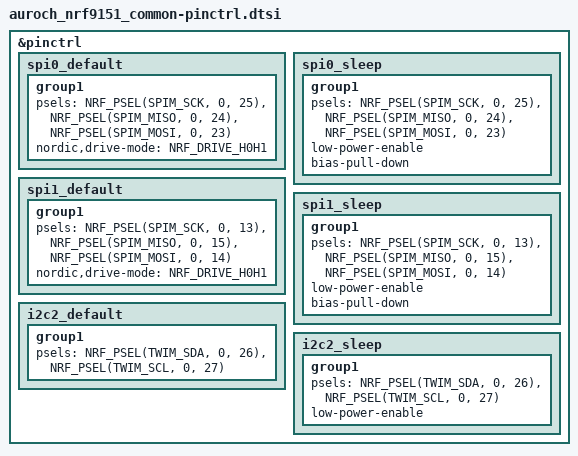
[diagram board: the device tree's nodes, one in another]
/*
 * Copyright (c) 2025 Embeint Holdings Pty Ltd
 * SPDX-License-Identifier: Apache-2.0
 */

&pinctrl {
	spi0_default: spi0_default {
		group1 {
			psels = <NRF_PSEL(SPIM_SCK, 0, 25)>,
				<NRF_PSEL(SPIM_MISO, 0, 24)>,
				<NRF_PSEL(SPIM_MOSI, 0, 23)>;
			nordic,drive-mode = <NRF_DRIVE_H0H1>;
		};
	};

	spi0_sleep: spi0_sleep {
		group1 {
			psels = <NRF_PSEL(SPIM_SCK, 0, 25)>,
				<NRF_PSEL(SPIM_MISO, 0, 24)>,
				<NRF_PSEL(SPIM_MOSI, 0, 23)>;
			low-power-enable;
			bias-pull-down;
		};
	};

	spi1_default: spi1_default {
		group1 {
			psels = <NRF_PSEL(SPIM_SCK, 0, 13)>,
				<NRF_PSEL(SPIM_MISO, 0, 15)>,
				<NRF_PSEL(SPIM_MOSI, 0, 14)>;
			nordic,drive-mode = <NRF_DRIVE_H0H1>;
		};
	};

	spi1_sleep: spi1_sleep {
		group1 {
			psels = <NRF_PSEL(SPIM_SCK, 0, 13)>,
				<NRF_PSEL(SPIM_MISO, 0, 15)>,
				<NRF_PSEL(SPIM_MOSI, 0, 14)>;
			low-power-enable;
			bias-pull-down;
		};
	};

	i2c2_default: i2c2_default {
		group1 {
			psels = <NRF_PSEL(TWIM_SDA, 0, 26)>,
				<NRF_PSEL(TWIM_SCL, 0, 27)>;
		};
	};

	i2c2_sleep: i2c2_sleep {
		group1 {
			psels = <NRF_PSEL(TWIM_SDA, 0, 26)>,
				<NRF_PSEL(TWIM_SCL, 0, 27)>;
			low-power-enable;
		};
	};
};
